# COMPUTE_CLUSTER0_SS_CFG register map
Vendor: Texas Instruments
Peripheral module from a debugger description file (folder J7ES).
Registers are 32-bit, read-write, reset 0x0 unless marked. A register's access mark holds for its fields unless they carry their own. Offsets are as the file gives them; lines under a group give offsets from that group; [hi:lo] are bit positions; {n}, {i} and the like mark numbered series; 'fields as' and 'values as' point back to an identical list; <NAME> marks a mode.

## COMPUTE_CLUSTER0_SS_CFG
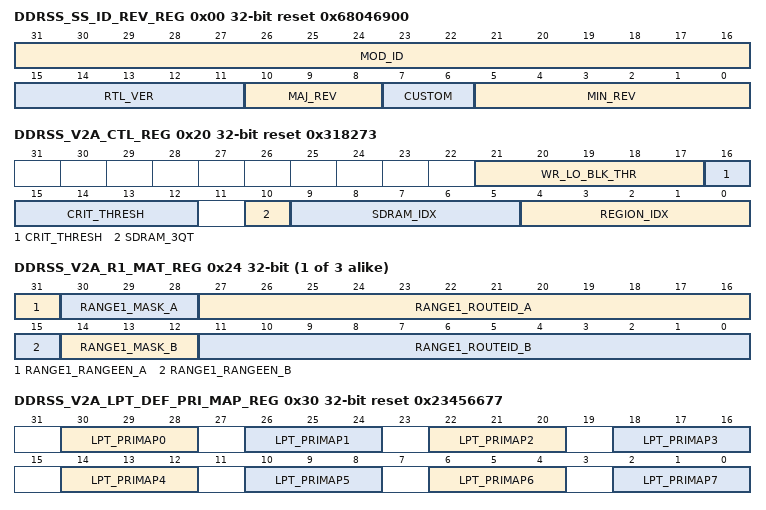
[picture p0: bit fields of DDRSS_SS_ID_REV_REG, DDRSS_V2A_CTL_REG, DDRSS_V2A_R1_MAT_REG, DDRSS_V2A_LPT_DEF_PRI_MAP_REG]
0x00 DDRSS_SS_ID_REV_REG ro reset 0x68046900 — The Subsystem ID and Revision Register contains the module ID, major, and minor revisions for the subsystem.
  [31:16] MOD_ID — Module ID
  [15:11] RTL_VER — RTL version
  [10:8] MAJ_REV — Major revision
  [7:6] CUSTOM
  [5:0] MIN_REV — Minor revision
0x04 DDRSS_SS_CTL_REG — The Subsystem Control Register contains fields for control functions required for submodules in the subsystem.
  [0] PHY_PLL_BYPASS — PHY De-Skew PLL bypass.
0x20 DDRSS_V2A_CTL_REG reset 0x318273 — The MSMC2DDR Bridge Control register contains control functions required for the MSMC2DDR bridge submodule.
  [21:17] WR_LO_BLK_THR — Write data threshold in 64 byte quantas.
  [16:12] CRIT_THRESH — Critical threshold.
  [10] SDRAM_3QT — Setting this field to a 1 will modify SDRAM Index to be 3/4 its programmed value to support 3, 6, 12 and 24 GB sizes.
  [9:5] SDRAM_IDX — SDRAM Index = log2(connected SDRAM size) - 16.
  [4:0] REGION_IDX — Region Index = log2(CBA region size) - 16.
{0x20+4i} DDRSS_V2A_R{i}_MAT_REG (i=1..3) — The Range {i} Match Register allows a single master to a range of masters to change their priority mapping. This allows selective masters to be increased or decreased in effective priority. Range {i} Match Register uses the associated Range {i} Priority Map Register. The highest Range Match Register will take priority and will be used in case of multiple range matches.
  [31] RANGE{i}_RANGEEN_A — The range{i}_rangeen_a enables the RouteID AND'd with range{i}_mask_a to match the range{i}_routeid_a
  [30:28] RANGE{i}_MASK_A — The range{i}_mask_a allows a number of least significant bits to be ignored prior to the match of the routeid_a
  [27:16] RANGE{i}_ROUTEID_A — The range{i}_routeid_a is the value that is compared to the RouteID arriving on the command interface
  [15] RANGE{i}_RANGEEN_B — The range{i}_rangeen_b enables the RouteID AND'd with range{i}_mask_b to match the range{i}_routeid_b
  [14:12] RANGE{i}_MASK_B — The range{i}_mask_b allows a number of least significant bits to be ignored prior to the match of the routeid_b
  [11:0] RANGE{i}_ROUTEID_B — The range{i}_routeid_b is the value that is compared to the RouteID arriving on the command interface
0x30 DDRSS_V2A_LPT_DEF_PRI_MAP_REG reset 0x23456677 — The LPT Default Priority Mapping Register is the default map for the inbound VBUSM.C priority on the Low Priority Thread to AXI priority.
  [30-4n:28-4n] LPT_PRIMAP{n} (n=0..7) — The field contains AXI priority value for VBUSM.C priority {n}.
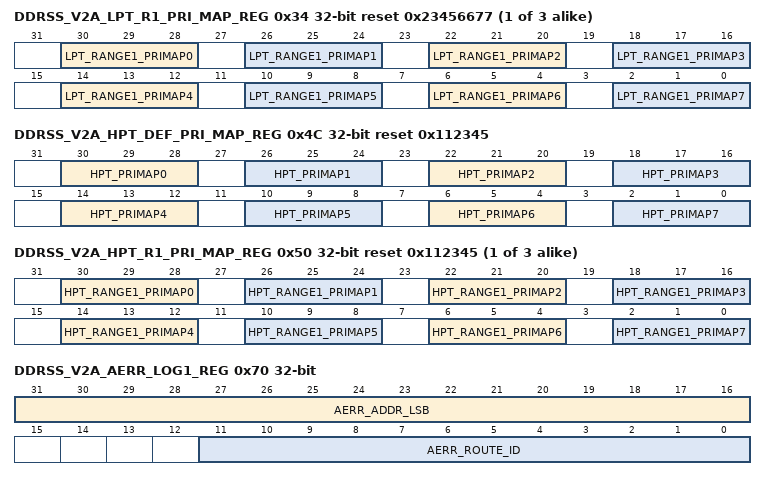
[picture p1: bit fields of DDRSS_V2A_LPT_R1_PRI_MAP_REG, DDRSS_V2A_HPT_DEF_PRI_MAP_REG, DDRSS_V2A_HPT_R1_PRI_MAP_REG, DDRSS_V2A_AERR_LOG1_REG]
{0x30+4i} DDRSS_V2A_LPT_R{i}_PRI_MAP_REG reset 0x23456677 (i=1..3) — The LPT Range {i} Priority Mapping Register is used to map the inbound VBUSM.C priority on the Low Priority Thread to AXI priority when a RouteID match {i} occurs. This allows the priority level to be changed from the LPT Default Priority Mapping value.
  [30-4n:28-4n] LPT_RANGE{i}_PRIMAP{n} (n=0..7) — The field contains AXI priority value for VBUSM.C priority {n} for range match {i}.
0x4C DDRSS_V2A_HPT_DEF_PRI_MAP_REG reset 0x112345 — The HPT Default Priority Mapping Register is the default map for the inbound VBUSM.C priority on the High Priority Thread to the AXI priority.
  [30-4n:28-4n] HPT_PRIMAP{n} (n=0..7) — The field contains AXI priority value for VBUSM.C priority {n}.
{0x4C+4i} DDRSS_V2A_HPT_R{i}_PRI_MAP_REG reset 0x112345 (i=1..3) — The HPT Range {i} Priority Mapping Register is used to map the inbound VBUSM.C priority on the High Priority Thread to AXI priority when a RouteID match {i} occurs. This allows the priority level to be changed from the HPT Default Priority Mapping value.
  [30-4n:28-4n] HPT_RANGE{i}_PRIMAP{n} (n=0..7) — The field contains AXI priority value for VBUSM.C priority {n} for range match {i}.
0x70 DDRSS_V2A_AERR_LOG1_REG access not given — The Address Error Log 1 register displays the RouteID and lsb of the address for the first VBUSM.C command that was outside the programmed addressing range. Writing a 0x1 will clear all fields. Writing any other value has no effect. The Address Error Log 2 register will also be cleared upon writing this register.
  [31:16] AERR_ADDR_LSB — Address (access RW1C)
  [11:0] AERR_ROUTE_ID — RouteID of the VBUSM.C write command (access RW1C)
0x74 DDRSS_V2A_AERR_LOG2_REG ro — The Address Error Log 2 registers displays the msb of the address for the first VBUSM.C command that was outside the programmed addressing range. This register will be cleared upon writing the Address Error Log 1 register.
  [31:0] AERR_ADDR_MSB — Address[47:16] of the VBUSM.C command
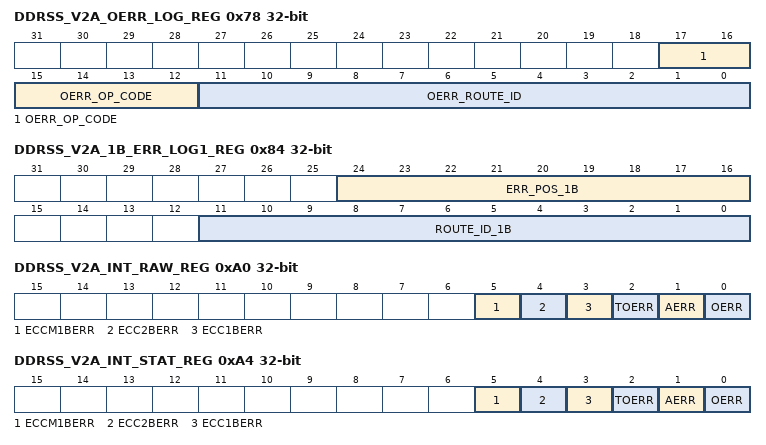
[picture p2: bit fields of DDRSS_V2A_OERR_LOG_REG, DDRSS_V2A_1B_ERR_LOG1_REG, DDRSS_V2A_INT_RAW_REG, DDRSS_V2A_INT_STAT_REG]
0x78 DDRSS_V2A_OERR_LOG_REG access not given — The Opcode Error Log register displays the RouteID and opcode for the first VBUSM.C command that had an unsupported opcode. Writing a 0x1 will clear all fields. Writing any other value has no effect.
  [17:12] OERR_OP_CODE — Opcode of the VBUSM.C command (access RW1C)
  [11:0] OERR_ROUTE_ID — RouteID of the VBUSM.C command (access RW1C)
0x80 DDRSS_V2A_1B_ERR_CNT_REG access not given — MSMC2DDR Bridge 1-Bit EDC Error Count Register
  [15:0] EDC_1B_ERR_CNT — (access RW1C)
0x84 DDRSS_V2A_1B_ERR_LOG1_REG access not given — The 1-Bit EDC Error Log 1 register displays the RouteID and error position of the first VBUSM.C write that incurred 1-bit EDC error. Writing a 0x1 will clear all fields. Writing any other value has no effect. The 1-Bit EDC Error Log 2 register will also be cleared upon writing this register.
  [24:16] ERR_POS_1B — Bit error position (access RW1C)
  [11:0] ROUTE_ID_1B — RouteID of the VBUSM.C write command (access RW1C)
0x88 DDRSS_V2A_1B_ERR_LOG2_REG ro — The 1-Bit EDC Error Log 2 registers displays the address of the first VBUSM.C write that incurred 1-bit EDC error. This register will be cleared upon writing the 1-Bit EDC Error Log 1 register.
  [29:0] ADDR_MSB_1B — Address
0x8C DDRSS_V2A_2B_ERR_LOG1_REG access not given — The 2-Bit EDC Error Log 1 register displays the RouteID of the first VBUSM.C write that incurred 2-bit EDC error. Writing a 0x1 clear all fields. Writing any other value has no effect. The 2-Bit EDC Error Log 2 register will also be cleared upon writing this register.
  [11:0] ROUTE_ID_2B — RouteID of the VBUSM.C write command (access RW1C)
0x90 DDRSS_V2A_2B_ERR_LOG2_REG ro — The 2-Bit EDC Error Log 1 register displays the address of the first VBUSM.C write that incurred 2-bit EDC error. This register will be cleared upon writing the 2-Bit EDC Error Log 1 register.
  [29:0] ADR_MSB_2B — Address
0x9C DDRSS_V2A_BUS_TO reset 0xFFFFFF — MSMC2DDR Bridge Bus Timeout Register
  [23:0] BUS_TIMER — AXI bus timeout value.
0xA0 DDRSS_V2A_INT_RAW_REG access not given — MSMC2DDR Bridge Interrupt Raw Status Register
  [5] ECCM1BERR — Raw status of SDRAM ECC multi 1-bit errors in same SDRAM burst. (access RW1S)
  [4] ECC2BERR — Raw status of SDRAM ECC 2-bit error. (access RW1S)
  [3] ECC1BERR — Raw status of SDRAM ECC 1-bit error. (access RW1S)
  [2] TOERR — Raw status of MSMC2DDR bridge interrupt for controller AXI interface timeout. (access RW1S)
  [1] AERR — Raw status of MSMC2DDR bridge interrupt for VBUSM.C address outside the programmed range. (access RW1S)
  [0] OERR — Raw status of MSMC2DDR bridge interrupt for VBUSM.C unsupported opcode. (access RW1S)
0xA4 DDRSS_V2A_INT_STAT_REG access not given — MSMC2DDR Bridge Interrupt Status Register
  [5] ECCM1BERR — Enabled status of SDRAM ECC multi 1-bit errors in same SDRAM burst. (access RW1C)
  [4] ECC2BERR — Enabled status of SDRAM ECC 2-bit error. (access RW1C)
  [3] ECC1BERR — Enabled status of SDRAM ECC 1-bit error. (access RW1C)
  [2] TOERR — Enabled status of MSMC2DDR bridge interrupt for controller AXI interface timeout. (access RW1C)
  [1] AERR — Enabled status of MSMC2DDR bridge interrupt for VBUSM.C address outside the programmed range. (access RW1C)
  [0] OERR — Enabled status of MSMC2DDR bridge interrupt for VBUSM.C unsupported opcode. (access RW1C)
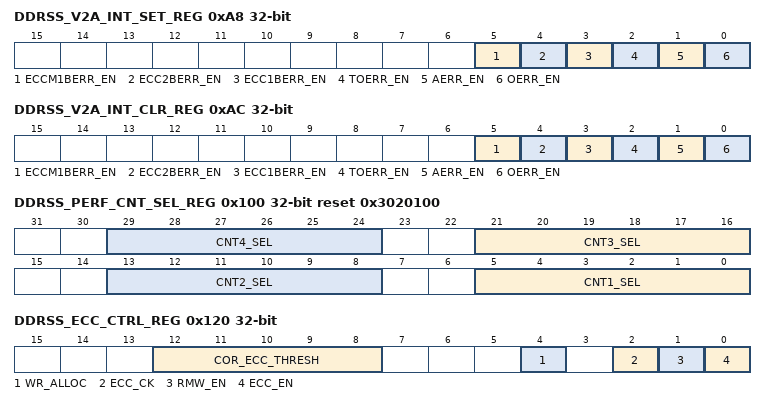
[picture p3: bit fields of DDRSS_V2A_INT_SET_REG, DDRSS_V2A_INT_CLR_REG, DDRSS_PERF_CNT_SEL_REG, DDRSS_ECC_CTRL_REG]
0xA8 DDRSS_V2A_INT_SET_REG access not given — MSMC2DDR Bridge Interrupt Enable Set Register
  [5] ECCM1BERR_EN — Enable set for SDRAM ECC multi (access RW1S)
  [4] ECC2BERR_EN — Enable set for SDRAM ECC (access RW1S)
  [3] ECC1BERR_EN — Enable set for SDRAM ECC (access RW1S)
  [2] TOERR_EN — Enable set for MSMC2DDR bridge interrupt for controller AXI interface timeout. (access RW1S)
  [1] AERR_EN — Enable set for MSMC2DDR bridge interrupt for VBUSM.C address outside the programmed range. (access RW1S)
  [0] OERR_EN — Enable set for MSMC2DDR bridge interrupt for VBUSM.C unsupported opcode. (access RW1S)
0xAC DDRSS_V2A_INT_CLR_REG access not given — MSMC2DDR Bridge Interrupt Enable Clear Register
  [5] ECCM1BERR_EN — Enable clear for SDRAM ECC multi (access RW1C)
  [4] ECC2BERR_EN — Enable clear for SDRAM ECC (access RW1C)
  [3] ECC1BERR_EN — Enable clear for SDRAM ECC (access RW1C)
  [2] TOERR_EN — Enable clear for MSMC2DDR bridge interrupt for controller AXI interface timeout. (access RW1C)
  [1] AERR_EN — Enable clear for MSMC2DDR bridge interrupt for VBUSM.C address outside the programmed range. (access RW1C)
  [0] OERR_EN — Enable clear for MSMC2DDR bridge interrupt for VBUSM.C unsupported opcode. (access RW1C)
0xB0 DDRSS_V2A_EOI_REG wo — MSMC2DDR Bridge End of Interrupt Register The EOI register is used to re-trigger the pulse interrupt signal to ensure that any nested interrupt events are serviced. The software interrupt handler must write to the EOI register at the end of the current interrupt processing routine, so that new events can re-trigger the pulse interrupt signal again. For level interrupt signals the EOI register is not functional and must not be used.
  [1:0] EOI — Software End Of Interrupt (EOI) control.
0x100 DDRSS_PERF_CNT_SEL_REG reset 0x3020100 — The Performance Counter Select register is used to select the statistic type to be counted in the corresponding Performance Counter register.
  [8n-3:8n-8] CNT{n}_SEL (n=1..4) — Statistic select for Performance Counter {n} register.
{0x100+4i} DDRSS_PERF_CNT{i}_REG ro (i=1..4) — Performance Counter {i} Register
  [31:0] CNT{i} — Soft 32-bit counter that can be configured as specified in the Performance Counter Select Register.
0x120 DDRSS_ECC_CTRL_REG — ECC Control Register
  [12:8] COR_ECC_THRESH — Threshold for
  [4] WR_ALLOC — When set to 1, an unassigned ECC cache-line will be allocated for a write with routeID that do not match any of the mapped routeID's.
  [2] ECC_CK — Set 1 to enable ECC verification for read accesses when ecc_en=1.
  [1] RMW_EN — Read modify write enable.
  [0] ECC_EN — DRAM ECC enable.
0x124 DDRSS_ECC_RID_INDX_REG — ECC Cache RouteID Index Register
  [6:0] ECCRID_ADR — This index specifies the ECC cache entry number that the eccrid_val is mapped to.
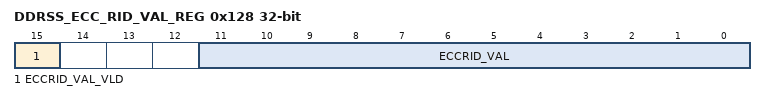
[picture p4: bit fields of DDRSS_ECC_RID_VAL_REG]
0x128 DDRSS_ECC_RID_VAL_REG — ECC Cache RouteID Write Value Register
  [15] ECCRID_VAL_VLD — A 1 in this field indicates that value in eccrid_val is valid.
  [11:0] ECCRID_VAL — RouteID value written or read.
{0x130+8i} DDRSS_ECC_R{i}_STR_ADDR_REG reset 0x7FFFF (i=0..2) — ECC Range {i} Start Address Register
  [18:0] ECC_STR_ADR_{i} — Start caddress
{0x134+8i} DDRSS_ECC_R{i}_END_ADDR_REG (i=0..2) — ECC Range {i} End Address Register
  [18:0] ECC_END_ADR_{i} — End caddress
0x150 DDRSS_ECC_1B_ERR_CNT_REG access not given — ECC 1-Bit Error Count Register
  [15:0] ECC_1B_ERR_CNT — (access RW1C)
0x154 DDRSS_ECC_1B_ERR_THRSH_REG — ECC 1-Bit Error Threshold Register
  [15:0] ECC_1B_ERR_THRSH — ECC
0x158 DDRSS_ECC_1B_ERR_ADR_LOG_REG access not given — ECC 1-Bit Error Address Log Register
  [28:0] ECC_1B_ERR_ADR — ECC (access RW1C)
0x15C DDRSS_ECC_1B_ERR_MSK_LOG_REG ro — ECC 1-Bit Error Mask Log Register
  [15:0] ECC_1B_ERR_MSK — ECC
0x160 DDRSS_ECC_2B_ERR_ADR_LOG_REG access not given — ECC 2-Bit Error Address Log Register
  [28:0] ECC_2B_ERR_ADR — ECC (access RW1C)
0x164 DDRSS_ECC_2B_ERR_MSK_LOG_REG ro — ECC 2-Bit Error Mask Log Register
  [15:0] ECC_2B_ERR_MSK — ECC
0x180 DDRSS_PHY_BIST_CTRL_REG — PHY BIST Control Register
  [15:0] BIST_TSEL_SELECT — This field controls the bist_tsel_select input of the PHY.
